# SAM9X60 device description
Architecture: ARM926EJS; Family: SAM9; Series: SAM9X
Registers are 32-bit, read-write, no defined reset value unless marked. A register's access mark holds for its fields unless they carry their own. Offsets are from the block's base; [hi:lo] are bit positions; {n}, {i} and the like mark numbered series; 'fields as' and 'values as' point back to an identical list; <NAME> marks a mode.

## FLEXCOM — Flexible Serial Communication
Instances: FLEXCOM{n} {0xF801C000+0x4000*n} (n=0..3), FLEXCOM4 0xF0000000, FLEXCOM5 0xF0004000, FLEXCOM6 0xF8010000, FLEXCOM7 0xF8014000, FLEXCOM8 0xF8018000, FLEXCOM9 0xF8040000, FLEXCOM10 0xF8044000, FLEXCOM11 0xF0020000, FLEXCOM12 0xF0024000
0x00 FLEX_MR — FLEXCOM Mode Register
  [1:0] OPMODE — FLEXCOM Operating Mode
    0=NO_COM (No communication); 1=USART (All UART related protocols are selected (RS232, RS485, IrDA, ISO7816, LIN, LON)SPI/TWI related registers are not accessible and have no impact on IOs.); 2=SPI (SPI operating mode is selected.USART/TWI related registers are not accessible and have no impact on IOs.); 3=TWI (All TWI related protocols are selected (TWI, SMBus).USART/SPI related registers are not accessible and have no impact on IOs.)
0x10 FLEX_RHR ro — FLEXCOM Receive Holding Register
  [15:0] RXDATA — Receive Data
0x20 FLEX_THR — FLEXCOM Transmit Holding Register
  [15:0] TXDATA — Transmit Data
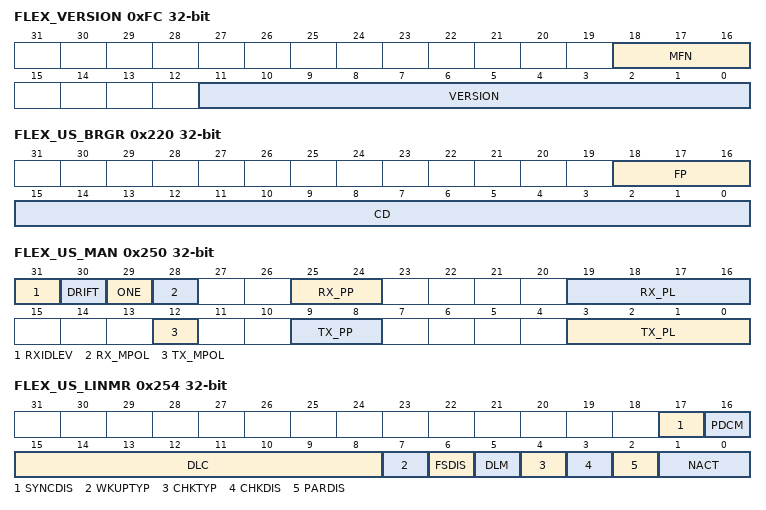
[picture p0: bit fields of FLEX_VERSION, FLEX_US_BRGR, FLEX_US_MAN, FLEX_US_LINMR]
0xFC FLEX_VERSION ro — FLEXCOM Version Register
  [18:16] MFN — Metal Fix Number
  [11:0] VERSION — Hardware Module Version
0x200 FLEX_US_CR wo — USART Control Register
  [31] FIFODIS <DEFAULT> — FIFO Disable
  [30] FIFOEN <DEFAULT> — FIFO Enable
  [28] REQCLR <DEFAULT> — Request to Clear the Comparison Trigger
  [26] TXFLCLR <DEFAULT> — Transmit FIFO Lock CLEAR
  [25] RXFCLR <DEFAULT> — Receive FIFO Clear
  [24] TXFCLR <DEFAULT> — Transmit FIFO Clear
  [21] LINWKUP <DEFAULT> — Send LIN Wakeup Signal
  [20] LINABT <DEFAULT> — Abort LIN Transmission
  [19] RTSDIS <DEFAULT> — Request to Send Disable
  [18] RTSEN <DEFAULT> — Request to Send Enable
  [17] DTRDIS <DEFAULT> — Data Terminal Ready Disable
  [16] DTREN <DEFAULT> — Data Terminal Ready Enable
  [15] RETTO <DEFAULT> — Start Timeout Immediately
  [14] RSTNACK <DEFAULT> — Reset Non Acknowledge
  [13] RSTIT <DEFAULT> — Reset Iterations
  [12] SENDA <DEFAULT> — Send Address
  [11] STTTO <DEFAULT> — Clear TIMEOUT Flag and Start Timeout After Next Character Received
  [10] STPBRK <DEFAULT> — Stop Break
  [9] STTBRK <DEFAULT> — Start Break
  [8] RSTSTA <DEFAULT> — Reset Status Bits
  [7] TXDIS <DEFAULT> — Transmitter Disable
  [6] TXEN <DEFAULT> — Transmitter Enable
  [5] RXDIS <DEFAULT> — Receiver Disable
  [4] RXEN <DEFAULT> — Receiver Enable
  [3] RSTTX <DEFAULT> — Reset Transmitter
  [2] RSTRX <DEFAULT> — Reset Receiver
  [19] RCS <SPI_MODE> — Release SPI Chip Select
  [18] FCS <SPI_MODE> — Force SPI Chip Select
  [8] RSTSTA <SPI_MODE> — Reset Status Bits
  [7] TXDIS <SPI_MODE> — Transmitter Disable
  [6] TXEN <SPI_MODE> — Transmitter Enable
  [5] RXDIS <SPI_MODE> — Receiver Disable
  [4] RXEN <SPI_MODE> — Receiver Enable
  [3] RSTTX <SPI_MODE> — Reset Transmitter
  [2] RSTRX <SPI_MODE> — Reset Receiver
0x204 FLEX_US_MR — USART Mode Register
  [31] ONEBIT <DEFAULT> — Start Frame Delimiter Selector
  [30] MODSYNC <DEFAULT> — Manchester Synchronization Mode
  [29] MAN <DEFAULT> — Manchester Encoder/Decoder Enable
  [28] FILTER <DEFAULT> — Receive Line Filter
  [26:24] MAX_ITERATION <DEFAULT> — Maximum Number of Automatic Iteration
  [23] INVDATA <DEFAULT> — Inverted Data
  [22] VAR_SYNC <DEFAULT> — Variable Synchronization of Command/Data Sync Start Frame Delimiter
  [21] DSNACK <DEFAULT> — Disable Successive NACK
  [20] INACK <DEFAULT> — Inhibit Non Acknowledge
  [19] OVER <DEFAULT> — Oversampling Mode
  [18] CLKO <DEFAULT> — Clock Output Select
  [17] MODE9 <DEFAULT> — 9-bit Character Length
  [16] MSBF <DEFAULT> — Bit Order
  [15:14] CHMODE <DEFAULT> — Channel Mode
    0=NORMAL (Normal mode); 1=AUTOMATIC (Automatic Echo. Receiver input is connected to the TXD pin.); 2=LOCAL_LOOPBACK (Local Loopback. Transmitter output is connected to the Receiver Input.); 3=REMOTE_LOOPBACK (Remote Loopback. RXD pin is internally connected to the TXD pin.)
  [13:12] NBSTOP <DEFAULT> — Number of Stop Bits
    0=_1_BIT (1 stop bit); 1=_1_5_BIT (1.5 stop bit (SYNC = 0) or reserved (SYNC = 1)); 2=_2_BIT (2 stop bits)
  [11:9] PAR <DEFAULT> — Parity Type
    0=EVEN (Even parity); 1=ODD (Odd parity); 2=SPACE (Parity forced to 0 (Space)); 3=MARK (Parity forced to 1 (Mark)); 4=NO (No parity); 6=MULTIDROP (Multidrop mode)
  [8] SYNC <DEFAULT> — Synchronous Mode Select
  [7:6] CHRL <DEFAULT> — Character Length
    {v}=_{v+5}_BIT (Character length is {v+5} bits) (v=0..3)
  [5:4] USCLKS <DEFAULT> — Clock Selection
    0=MCK (Peripheral clock is selected); 1=DIV (Peripheral clock divided (DIV = 8) is selected); 2=GCLK (PMC generic clock is selected. If the SCK pin is driven (CLKO = 1), the CD field must be greater than 1.); 3=SCK (External pin SCK is selected)
  [3:0] USART_MODE <DEFAULT> — USART Mode of Operation
    0=NORMAL (Normal mode); 1=RS485; 2=HW_HANDSHAKING (Hardware handshaking); 3=MODEM; 4=IS07816_T_0 (IS07816 Protocol: T = 0); 6=IS07816_T_1 (IS07816 Protocol: T = 1); 8=IRDA; 9=LON; 10=LIN_MASTER (LIN Master mode); 11=LIN_SLAVE (LIN Slave mode); 12=DATA16BIT_MASTER (16-bit data master); 13=DATA16BIT_SLAVE (16-bit data slave); 14=SPI_MASTER (SPI Master mode (CLKO must be written to 1 and USCLKS = 0, 1 or 2)); 15=SPI_SLAVE (SPI Slave mode)
  [20] WRDBT <SPI_MODE> — Wait Read Data Before Transfer
  [16] CPOL <SPI_MODE> — SPI Clock Polarity
  [15:14] CHMODE <SPI_MODE> — Channel Mode
    0=NORMAL (Normal mode)
  [8] CPHA <SPI_MODE> — SPI Clock Phase
  [7:6] CHRL <SPI_MODE> — Character Length
    3=_8_BIT (Character length is 8 bits)
  [5:4] USCLKS <SPI_MODE> — Clock Selection
    0=MCK (Peripheral clock is selected); 1=DIV (Peripheral clock Divided (DIV= 8) is selected); 2=GCLK (A PMC generic clock is selected); 3=SCK (External pin SCK is selected)
  [3:0] USART_MODE <SPI_MODE> — USART Mode of Operation
    14=SPI_MASTER; 15=SPI_SLAVE
0x208 FLEX_US_IER wo — USART Interrupt Enable Register
  [24] MANE <DEFAULT> — Manchester Error Interrupt Enable
  [22] CMP <DEFAULT> — Comparison Interrupt Enable
  [19] CTSIC <DEFAULT> — Clear to Send Input Change Interrupt Enable
  [18] DCDIC <DEFAULT> — Data Carrier Detect Input Change Interrupt Enable
  [17] DSRIC <DEFAULT> — Data Set Ready Input Change Enable
  [16] RIIC <DEFAULT> — Ring Indicator Input Change Enable
  [13] NACK <DEFAULT> — Non Acknowledge Interrupt Enable
  [10] ITER <DEFAULT> — Max number of Repetitions Reached Interrupt Enable
  [9] TXEMPTY <DEFAULT> — TXEMPTY Interrupt Enable
  [8] TIMEOUT <DEFAULT> — Timeout Interrupt Enable
  [7] PARE <DEFAULT> — Parity Error Interrupt Enable
  [6] FRAME <DEFAULT> — Framing Error Interrupt Enable
  [5] OVRE <DEFAULT> — Overrun Error Interrupt Enable
  [2] RXBRK <DEFAULT> — Receiver Break Interrupt Enable
  [1] TXRDY <DEFAULT> — TXRDY Interrupt Enable
  [0] RXRDY <DEFAULT> — RXRDY Interrupt Enable
  [31] LINHTE <LIN_MODE> — LIN Header Timeout Error Interrupt Enable
  [30] LINSTE <LIN_MODE> — LIN Synch Tolerance Error Interrupt Enable
  [29] LINSNRE <LIN_MODE> — LIN Slave Not Responding Error Interrupt Enable
  [28] LINCE <LIN_MODE> — LIN Checksum Error Interrupt Enable
  [27] LINIPE <LIN_MODE> — LIN Identifier Parity Interrupt Enable
  [26] LINISFE <LIN_MODE> — LIN Inconsistent Synch Field Error Interrupt Enable
  [25] LINBE <LIN_MODE> — LIN Bus Error Interrupt Enable
  [15] LINTC <LIN_MODE> — LIN Transfer Completed Interrupt Enable
  [14] LINID <LIN_MODE> — LIN Identifier Sent or LIN Identifier Received Interrupt Enable
  [13] LINBK <LIN_MODE> — LIN Break Sent or LIN Break Received Interrupt Enable
  [9] TXEMPTY <LIN_MODE> — TXEMPTY Interrupt Enable
  [8] TIMEOUT <LIN_MODE> — Timeout Interrupt Enable
  [7] PARE <LIN_MODE> — Parity Error Interrupt Enable
  [6] FRAME <LIN_MODE> — Framing Error Interrupt Enable
  [5] OVRE <LIN_MODE> — Overrun Error Interrupt Enable
  [1] TXRDY <LIN_MODE> — TXRDY Interrupt Enable
  [0] RXRDY <LIN_MODE> — RXRDY Interrupt Enable
  [28] LBLOVFE <LON_MODE> — LON Backlog Overflow Error Interrupt Enable
  [27] LRXD <LON_MODE> — LON Reception Done Interrupt Enable
  [26] LFET <LON_MODE> — LON Frame Early Termination Interrupt Enable
  [25] LCOL <LON_MODE> — LON Collision Interrupt Enable
  [24] LTXD <LON_MODE> — LON Transmission Done Interrupt Enable
  [10] UNRE <LON_MODE> — Underrun Error Interrupt Enable
  [9] TXEMPTY <LON_MODE> — TXEMPTY Interrupt Enable
  [7] LCRCE <LON_MODE> — LON CRC Error Interrupt Enable
  [6] LSFE <LON_MODE> — LON Short Frame Error Interrupt Enable
  [5] OVRE <LON_MODE> — Overrun Error Interrupt Enable
  [1] TXRDY <LON_MODE> — TXRDY Interrupt Enable
  [0] RXRDY <LON_MODE> — RXRDY Interrupt Enable
  [22] CMP <SPI_MODE> — Comparison Interrupt Enable
  [19] NSSE <SPI_MODE> — NSS Line (Driving CTS Pin) Rising or Falling Edge Event
  [10] UNRE <SPI_MODE> — SPI Underrun Error Interrupt Enable
  [9] TXEMPTY <SPI_MODE> — TXEMPTY Interrupt Enable
  [5] OVRE <SPI_MODE> — Overrun Error Interrupt Enable
  [1] TXRDY <SPI_MODE> — TXRDY Interrupt Enable
  [0] RXRDY <SPI_MODE> — RXRDY Interrupt Enable
0x20C FLEX_US_IDR wo — USART Interrupt Disable Register
  [24] MANE <DEFAULT> — Manchester Error Interrupt Disable
  [22] CMP <DEFAULT> — Comparison Interrupt Disable
  [19] CTSIC <DEFAULT> — Clear to Send Input Change Interrupt Disable
  [18] DCDIC <DEFAULT> — Data Carrier Detect Input Change Interrupt Disable
  [17] DSRIC <DEFAULT> — Data Set Ready Input Change Disable
  [16] RIIC <DEFAULT> — Ring Indicator Input Change Disable
  [13] NACK <DEFAULT> — Non Acknowledge Interrupt Disable
  [10] ITER <DEFAULT> — Max Number of Repetitions Reached Interrupt Disable
  [9] TXEMPTY <DEFAULT> — TXEMPTY Interrupt Disable
  [8] TIMEOUT <DEFAULT> — Timeout Interrupt Disable
  [7] PARE <DEFAULT> — Parity Error Interrupt Disable
  [6] FRAME <DEFAULT> — Framing Error Interrupt Disable
  [5] OVRE <DEFAULT> — Overrun Error Interrupt Enable
  [2] RXBRK <DEFAULT> — Receiver Break Interrupt Disable
  [1] TXRDY <DEFAULT> — TXRDY Interrupt Disable
  [0] RXRDY <DEFAULT> — RXRDY Interrupt Disable
  [31] LINHTE <LIN_MODE> — LIN Header Timeout Error Interrupt Disable
  [30] LINSTE <LIN_MODE> — LIN Synch Tolerance Error Interrupt Disable
  [29] LINSNRE <LIN_MODE> — LIN Slave Not Responding Error Interrupt Disable
  [28] LINCE <LIN_MODE> — LIN Checksum Error Interrupt Disable
  [27] LINIPE <LIN_MODE> — LIN Identifier Parity Interrupt Disable
  [26] LINISFE <LIN_MODE> — LIN Inconsistent Synch Field Error Interrupt Disable
  [25] LINBE <LIN_MODE> — LIN Bus Error Interrupt Disable
  [15] LINTC <LIN_MODE> — LIN Transfer Completed Interrupt Disable
  [14] LINID <LIN_MODE> — LIN Identifier Sent or LIN Identifier Received Interrupt Disable
  [13] LINBK <LIN_MODE> — LIN Break Sent or LIN Break Received Interrupt Disable
  [9] TXEMPTY <LIN_MODE> — TXEMPTY Interrupt Disable
  [8] TIMEOUT <LIN_MODE> — Timeout Interrupt Disable
  [7] PARE <LIN_MODE> — Parity Error Interrupt Disable
  [6] FRAME <LIN_MODE> — Framing Error Interrupt Disable
  [5] OVRE <LIN_MODE> — Overrun Error Interrupt Disable
  [1] TXRDY <LIN_MODE> — TXRDY Interrupt Disable
  [0] RXRDY <LIN_MODE> — RXRDY Interrupt Disable
  [28] LBLOVFE <LON_MODE> — LON Backlog Overflow Error Interrupt Disable
  [27] LRXD <LON_MODE> — LON Reception Done Interrupt Disable
  [26] LFET <LON_MODE> — LON Frame Early Termination Interrupt Disable
  [25] LCOL <LON_MODE> — LON Collision Interrupt Disable
  [24] LTXD <LON_MODE> — LON Transmission Done Interrupt Disable
  [10] UNRE <LON_MODE> — Underrun Error Interrupt Disable
  [9] TXEMPTY <LON_MODE> — TXEMPTY Interrupt Disable
  [7] LCRCE <LON_MODE> — LON CRC Error Interrupt Disable
  [6] LSFE <LON_MODE> — LON Short Frame Error Interrupt Disable
  [5] OVRE <LON_MODE> — Overrun Error Interrupt Disable
  [1] TXRDY <LON_MODE> — TXRDY Interrupt Disable
  [0] RXRDY <LON_MODE> — RXRDY Interrupt Disable
  [22] CMP <SPI_MODE> — Comparison Interrupt Disable
  [19] NSSE <SPI_MODE> — NSS Line (Driving CTS Pin) Rising or Falling Edge Event
  [10] UNRE <SPI_MODE> — SPI Underrun Error Interrupt Disable
  [9] TXEMPTY <SPI_MODE> — TXEMPTY Interrupt Disable
  [5] OVRE <SPI_MODE> — Overrun Error Interrupt Disable
  [1] TXRDY <SPI_MODE> — TXRDY Interrupt Disable
  [0] RXRDY <SPI_MODE> — RXRDY Interrupt Disable
0x210 FLEX_US_IMR ro — USART Interrupt Mask Register
  [24] MANE <DEFAULT> — Manchester Error Interrupt Mask
  [22] CMP <DEFAULT> — Comparison Interrupt Mask
  [19] CTSIC <DEFAULT> — Clear to Send Input Change Interrupt Mask
  [18] DCDIC <DEFAULT> — Data Carrier Detect Input Change Interrupt Mask
  [17] DSRIC <DEFAULT> — Data Set Ready Input Change Mask
  [16] RIIC <DEFAULT> — Ring Indicator Input Change Mask
  [13] NACK <DEFAULT> — Non Acknowledge Interrupt Mask
  [10] ITER <DEFAULT> — Max Number of Repetitions Reached Interrupt Mask
  [9] TXEMPTY <DEFAULT> — TXEMPTY Interrupt Mask
  [8] TIMEOUT <DEFAULT> — Timeout Interrupt Mask
  [7] PARE <DEFAULT> — Parity Error Interrupt Mask
  [6] FRAME <DEFAULT> — Framing Error Interrupt Mask
  [5] OVRE <DEFAULT> — Overrun Error Interrupt Mask
  [2] RXBRK <DEFAULT> — Receiver Break Interrupt Mask
  [1] TXRDY <DEFAULT> — TXRDY Interrupt Mask
  [0] RXRDY <DEFAULT> — RXRDY Interrupt Mask
  [31] LINHTE <LIN_MODE> — LIN Header Timeout Error Interrupt Mask
  [30] LINSTE <LIN_MODE> — LIN Synch Tolerance Error Interrupt Mask
  [29] LINSNRE <LIN_MODE> — LIN Slave Not Responding Error Interrupt Mask
  [28] LINCE <LIN_MODE> — LIN Checksum Error Interrupt Mask
  [27] LINIPE <LIN_MODE> — LIN Identifier Parity Interrupt Mask
  [26] LINISFE <LIN_MODE> — LIN Inconsistent Synch Field Error Interrupt Mask
  [25] LINBE <LIN_MODE> — LIN Bus Error Interrupt Mask
  [15] LINTC <LIN_MODE> — LIN Transfer Completed Interrupt Mask
  [14] LINID <LIN_MODE> — LIN Identifier Sent or LIN Identifier Received Interrupt Mask
  [13] LINBK <LIN_MODE> — LIN Break Sent or LIN Break Received Interrupt Mask
  [9] TXEMPTY <LIN_MODE> — TXEMPTY Interrupt Mask
  [8] TIMEOUT <LIN_MODE> — Timeout Interrupt Mask
  [7] PARE <LIN_MODE> — Parity Error Interrupt Mask
  [6] FRAME <LIN_MODE> — Framing Error Interrupt Mask
  [5] OVRE <LIN_MODE> — Overrun Error Interrupt Mask
  [1] TXRDY <LIN_MODE> — TXRDY Interrupt Mask
  [0] RXRDY <LIN_MODE> — RXRDY Interrupt Mask
  [28] LBLOVFE <LON_MODE> — LON Backlog Overflow Error Interrupt Mask
  [27] LRXD <LON_MODE> — LON Reception Done Interrupt Mask
  [26] LFET <LON_MODE> — LON Frame Early Termination Interrupt Mask
  [25] LCOL <LON_MODE> — LON Collision Interrupt Mask
  [24] LTXD <LON_MODE> — LON Transmission Done Interrupt Mask
  [10] UNRE <LON_MODE> — Underrun Error Interrupt Mask
  [9] TXEMPTY <LON_MODE> — TXEMPTY Interrupt Mask
  [7] LCRCE <LON_MODE> — LON CRC Error Interrupt Mask
  [6] LSFE <LON_MODE> — LON Short Frame Error Interrupt Mask
  [5] OVRE <LON_MODE> — Overrun Error Interrupt Mask
  [1] TXRDY <LON_MODE> — TXRDY Interrupt Mask
  [0] RXRDY <LON_MODE> — RXRDY Interrupt Mask
  [22] CMP <SPI_MODE> — Comparison Interrupt Mask
  [19] NSSE <SPI_MODE> — NSS Line (Driving CTS Pin) Rising or Falling Edge Event
  [10] UNRE <SPI_MODE> — SPI Underrun Error Interrupt Mask
  [9] TXEMPTY <SPI_MODE> — TXEMPTY Interrupt Mask
  [5] OVRE <SPI_MODE> — Overrun Error Interrupt Mask
  [1] TXRDY <SPI_MODE> — TXRDY Interrupt Mask
  [0] RXRDY <SPI_MODE> — RXRDY Interrupt Mask
0x214 FLEX_US_CSR ro — USART Channel Status Register
  [24] MANE <DEFAULT> — Manchester Error
  [23] CTS <DEFAULT> — Image of CTS Input
  [22] CMP <DEFAULT> — Comparison Status
  [19] CTSIC <DEFAULT> — Clear to Send Input Change Flag
  [18] DCDIC <DEFAULT> — Data Carrier Detect Input Change Flag
  [17] DSRIC <DEFAULT> — Data Set Ready Input Change Flag
  [16] RIIC <DEFAULT> — Ring Indicator Input Change Flag
  [13] NACK <DEFAULT> — Non Acknowledge Interrupt
  [10] ITER <DEFAULT> — Max Number of Repetitions Reached
  [9] TXEMPTY <DEFAULT> — Transmitter Empty (cleared by writing FLEX_US_THR)
  [8] TIMEOUT <DEFAULT> — Receiver Timeout
  [7] PARE <DEFAULT> — Parity Error
  [6] FRAME <DEFAULT> — Framing Error
  [5] OVRE <DEFAULT> — Overrun Error
  [2] RXBRK <DEFAULT> — Break Received/End of Break
  [1] TXRDY <DEFAULT> — Transmitter Ready (cleared by writing FLEX_US_THR)
  [0] RXRDY <DEFAULT> — Receiver Ready (cleared by reading FLEX_US_RHR)
  [31] LINHTE <LIN_MODE> — LIN Header Timeout Error
  [30] LINSTE <LIN_MODE> — LIN Synch Tolerance Error
  [29] LINSNRE <LIN_MODE> — LIN Slave Not Responding Error
  [28] LINCE <LIN_MODE> — LIN Checksum Error
  [27] LINIPE <LIN_MODE> — LIN Identifier Parity Error
  [26] LINISFE <LIN_MODE> — LIN Inconsistent Synch Field Error
  [25] LINBE <LIN_MODE> — LIN Bit Error
  [23] LINBLS <LIN_MODE> — LIN Bus Line Status
  [15] LINTC <LIN_MODE> — LIN Transfer Completed
  [14] LINID <LIN_MODE> — LIN Identifier Sent or LIN Identifier Received
  [13] LINBK <LIN_MODE> — LIN Break Sent or LIN Break Received
  [9] TXEMPTY <LIN_MODE> — Transmitter Empty (cleared by writing FLEX_US_THR)
  [8] TIMEOUT <LIN_MODE> — Receiver Timeout
  [7] PARE <LIN_MODE> — Parity Error
  [6] FRAME <LIN_MODE> — Framing Error
  [5] OVRE <LIN_MODE> — Overrun Error
  [1] TXRDY <LIN_MODE> — Transmitter Ready (cleared by writing FLEX_US_THR)
  [0] RXRDY <LIN_MODE> — Receiver Ready (cleared by reading FLEX_US_RHR)
  [28] LBLOVFE <LON_MODE> — LON Backlog Overflow Error
  [27] LRXD <LON_MODE> — LON Reception End Flag
  [26] LFET <LON_MODE> — LON Frame Early Termination
  [25] LCOL <LON_MODE> — LON Collision Detected Flag
  [24] LTXD <LON_MODE> — LON Transmission End Flag
  [10] UNRE <LON_MODE> — Underrun Error
  [9] TXEMPTY <LON_MODE> — Transmitter Empty (cleared by writing FLEX_US_THR)
  [7] LCRCE <LON_MODE> — LON CRC Error
  [6] LSFE <LON_MODE> — LON Short Frame Error
  [5] OVRE <LON_MODE> — Overrun Error
  [1] TXRDY <LON_MODE> — Transmitter Ready (cleared by writing FLEX_US_THR)
  [0] RXRDY <LON_MODE> — Receiver Ready (cleared by reading FLEX_US_RHR)
  [23] NSS <SPI_MODE> — NSS Line (Driving CTS Pin) Rising or Falling Edge Event (cleared on read)
  [22] CMP <SPI_MODE> — Comparison Match
  [19] NSSE <SPI_MODE> — NSS Line (Driving CTS Pin) Rising or Falling Edge Event (cleared on read)
  [10] UNRE <SPI_MODE> — Underrun Error
  [9] TXEMPTY <SPI_MODE> — Transmitter Empty (cleared by writing FLEX_US_THR)
  [5] OVRE <SPI_MODE> — Overrun Error
  [1] TXRDY <SPI_MODE> — Transmitter Ready (cleared by writing FLEX_US_THR)
  [0] RXRDY <SPI_MODE> — Receiver Ready (cleared by reading FLEX_US_RHR)
0x218 FLEX_US_RHR ro — USART Receive Holding Register
  [15] RXSYNH <DEFAULT> — Received Sync
  [8:0] RXCHR <DEFAULT> — Received Character
  [8n+7:8n] RXCHR{n} <FIFO_MULTI_DATA> (n=0..3) — Received Character
0x21C FLEX_US_THR wo — USART Transmit Holding Register
  [15] TXSYNH <DEFAULT> — Sync Field to be Transmitted
  [8:0] TXCHR <DEFAULT> — Character to be Transmitted
  [8n+7:8n] TXCHR{n} <FIFO_MULTI_DATA> (n=0..3) — Character to be Transmitted
0x220 FLEX_US_BRGR — USART Baud Rate Generator Register
  [18:16] FP — Fractional Part
  [15:0] CD — Clock Divider
0x224 FLEX_US_RTOR — USART Receiver Timeout Register
  [16:0] TO — Timeout Value
0x228 FLEX_US_TTGR — USART Transmitter Timeguard Register
  [7:0] TG <DEFAULT> — Timeguard Value
  [23:0] PCYCLE <LON_MODE> — LON PCYCLE Length
0x240 FLEX_US_FIDI — USART FI DI Ratio Register
  [15:0] FI_DI_RATIO <DEFAULT> — FI Over DI Ratio Value
  [23:0] BETA2 <LON_MODE> — LON BETA2 Length
0x244 FLEX_US_NER ro — USART Number of Errors Register
  [7:0] NB_ERRORS — Number of Errors
0x24C FLEX_US_IF — USART IrDA Filter Register
  [7:0] IRDA_FILTER
0x250 FLEX_US_MAN — USART Manchester Configuration Register
  [31] RXIDLEV — Receiver Idle Value
  [30] DRIFT — Drift Compensation
  [29] ONE — Must Be Set to 1
  [28] RX_MPOL — Receiver Manchester Polarity
  [25:24] RX_PP — Receiver Preamble Pattern detected
    0=ALL_ONE (The preamble is composed of '1's); 1=ALL_ZERO (The preamble is composed of '0's); 2=ZERO_ONE (The preamble is composed of '01's); 3=ONE_ZERO (The preamble is composed of '10's)
  [19:16] RX_PL — Receiver Preamble Length
  [12] TX_MPOL — Transmitter Manchester Polarity
  [9:8] TX_PP — Transmitter Preamble Pattern
    values as RX_PP
  [3:0] TX_PL — Transmitter Preamble Length
0x254 FLEX_US_LINMR — USART LIN Mode Register
  [17] SYNCDIS — Synchronization Disable
  [16] PDCM — DMA Mode
  [15:8] DLC — Data Length Control
  [7] WKUPTYP — Wakeup Signal Type
  [6] FSDIS — Frame Slot Mode Disable
  [5] DLM — Data Length Mode
  [4] CHKTYP — Checksum Type
  [3] CHKDIS — Checksum Disable
  [2] PARDIS — Parity Disable
  [1:0] NACT — LIN Node Action
    0=PUBLISH (The USART transmits the response.); 1=SUBSCRIBE (The USART receives the response.); 2=IGNORE (The USART does not transmit and does not receive the response.)
0x258 FLEX_US_LINIR — USART LIN Identifier Register
  [7:0] IDCHR — Identifier Character
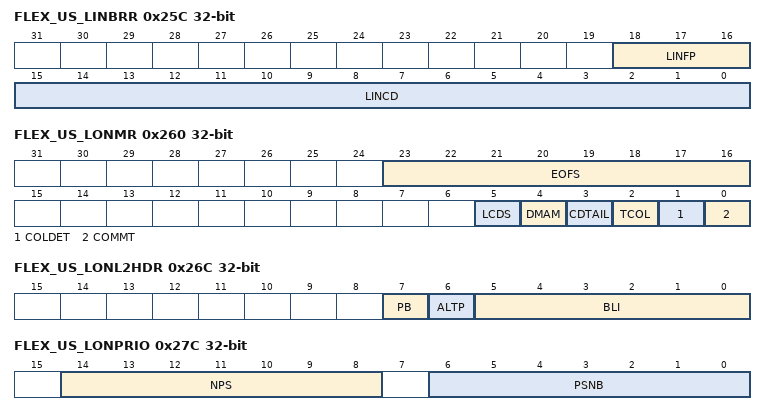
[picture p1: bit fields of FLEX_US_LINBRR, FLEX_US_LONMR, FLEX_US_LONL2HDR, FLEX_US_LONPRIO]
0x25C FLEX_US_LINBRR ro — USART LIN Baud Rate Register
  [18:16] LINFP — Fractional Part after Synchronization
  [15:0] LINCD — Clock Divider after Synchronization
0x260 FLEX_US_LONMR — USART LON Mode Register
  [23:16] EOFS — End of Frame Condition Size
  [5] LCDS — LON Collision Detection Source
  [4] DMAM — LON DMA Mode
  [3] CDTAIL — LON Collision Detection on Frame Tail
  [2] TCOL — Terminate Frame upon Collision Notification
  [1] COLDET — LON Collision Detection Feature
  [0] COMMT — LON comm_type Parameter Value
0x264 FLEX_US_LONPR — USART LON Preamble Register
  [13:0] LONPL — LON Preamble Length
0x268 FLEX_US_LONDL — USART LON Data Length Register
  [7:0] LONDL — LON Data Length
0x26C FLEX_US_LONL2HDR — USART LON L2HDR Register
  [7] PB — LON Priority Bit
  [6] ALTP — LON Alternate Path Bit
  [5:0] BLI — LON Backlog Increment
0x270 FLEX_US_LONBL ro — USART LON Backlog Register
  [5:0] LONBL — LON Node Backlog Value
0x274 FLEX_US_LONB1TX — USART LON Beta1 Tx Register
  [23:0] BETA1TX — LON Beta1 Length after Transmission
0x278 FLEX_US_LONB1RX — USART LON Beta1 Rx Register
  [23:0] BETA1RX — LON Beta1 Length after Reception
0x27C FLEX_US_LONPRIO — USART LON Priority Register
  [14:8] NPS — LON Node Priority Slot
  [6:0] PSNB — LON Priority Slot Number
0x280 FLEX_US_IDTTX — USART LON IDT Tx Register
  [23:0] IDTTX — LON Indeterminate Time after Transmission (comm_type = 1 mode only)
0x284 FLEX_US_IDTRX — USART LON IDT Rx Register
  [23:0] IDTRX — LON Indeterminate Time after Reception (comm_type = 1 mode only)
0x288 FLEX_US_ICDIFF — USART IC DIFF Register
  [3:0] ICDIFF — IC Differentiator Number
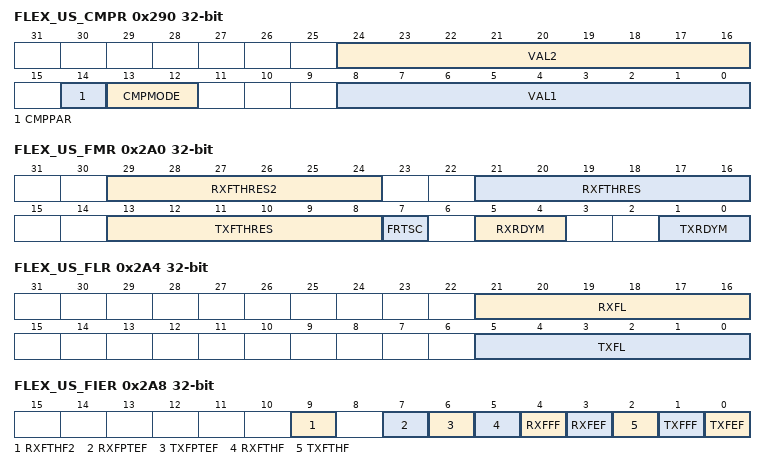
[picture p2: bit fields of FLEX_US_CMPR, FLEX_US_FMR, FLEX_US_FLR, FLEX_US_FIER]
0x290 FLEX_US_CMPR — USART Comparison Register
  [24:16] VAL2 — Second Comparison Value for Received Character
  [14] CMPPAR — Compare Parity
  [13:12] CMPMODE — Comparison Mode
    0=FLAG_ONLY (Any character is received and comparison function drives CMP flag.); 1=START_CONDITION (Comparison condition must be met to start reception.); 2=FILTER (Comparison must be met to receive the current data only)
  [8:0] VAL1 — First Comparison Value for Received Character
0x2A0 FLEX_US_FMR — USART FIFO Mode Register
  [29:24] RXFTHRES2 — Receive FIFO Threshold 2
  [21:16] RXFTHRES — Receive FIFO Threshold
  [13:8] TXFTHRES — Transmit FIFO Threshold
  [7] FRTSC — FIFO RTS Pin Control enable (Hardware Handshaking mode only)
  [5:4] RXRDYM — Receiver Ready Mode
    0=ONE_DATA (RXRDY will be at level '1' when at least one unread data is in the Receive FIFO); 1=TWO_DATA (RXRDY will be at level '1' when at least two unread data are in the Receive FIFO); 2=FOUR_DATA (RXRDY will be at level '1' when at least four unread data are in the Receive FIFO)
  [1:0] TXRDYM — Transmitter Ready Mode
    0=ONE_DATA (TXRDY will be at level '1' when at least one data can be written in the Transmit FIFO); 1=TWO_DATA (TXRDY will be at level '1' when at least two data can be written in the Transmit FIFO); 2=FOUR_DATA (TXRDY will be at level '1' when at least four data can be written in the Transmit FIFO)
0x2A4 FLEX_US_FLR ro — USART FIFO Level Register
  [21:16] RXFL — Receive FIFO Level
  [5:0] TXFL — Transmit FIFO Level
0x2A8 FLEX_US_FIER wo — USART FIFO Interrupt Enable Register
  [9] RXFTHF2 — RXFTHF2 Interrupt Enable
  [7] RXFPTEF — RXFPTEF Interrupt Enable
  [6] TXFPTEF — TXFPTEF Interrupt Enable
  [5] RXFTHF — RXFTHF Interrupt Enable
  [4] RXFFF — RXFFF Interrupt Enable
  [3] RXFEF — RXFEF Interrupt Enable
  [2] TXFTHF — TXFTHF Interrupt Enable
  [1] TXFFF — TXFFF Interrupt Enable
  [0] TXFEF — TXFEF Interrupt Enable
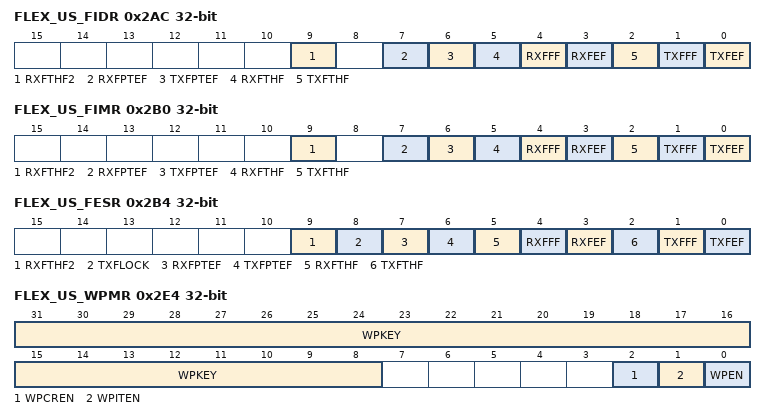
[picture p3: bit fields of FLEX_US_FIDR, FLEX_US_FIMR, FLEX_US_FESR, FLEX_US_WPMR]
0x2AC FLEX_US_FIDR wo — USART FIFO Interrupt Disable Register
  [9] RXFTHF2 — RXFTHF2 Interrupt Disable
  [7] RXFPTEF — RXFPTEF Interrupt Disable
  [6] TXFPTEF — TXFPTEF Interrupt Disable
  [5] RXFTHF — RXFTHF Interrupt Disable
  [4] RXFFF — RXFFF Interrupt Disable
  [3] RXFEF — RXFEF Interrupt Disable
  [2] TXFTHF — TXFTHF Interrupt Disable
  [1] TXFFF — TXFFF Interrupt Disable
  [0] TXFEF — TXFEF Interrupt Disable
0x2B0 FLEX_US_FIMR ro — USART FIFO Interrupt Mask Register
  [9] RXFTHF2 — RXFTHF2 Interrupt Mask
  [7] RXFPTEF — RXFPTEF Interrupt Mask
  [6] TXFPTEF — TXFPTEF Interrupt Mask
  [5] RXFTHF — RXFTHF Interrupt Mask
  [4] RXFFF — RXFFF Interrupt Mask
  [3] RXFEF — RXFEF Interrupt Mask
  [2] TXFTHF — TXFTHF Interrupt Mask
  [1] TXFFF — TXFFF Interrupt Mask
  [0] TXFEF — TXFEF Interrupt Mask
0x2B4 FLEX_US_FESR ro — USART FIFO Event Status Register
  [9] RXFTHF2 — Receive FIFO Threshold Flag 2 (cleared by writing the FLEX_US_CR.RSTSTA bit)
  [8] TXFLOCK — Transmit FIFO Lock
  [7] RXFPTEF — Receive FIFO Pointer Error Flag
  [6] TXFPTEF — Transmit FIFO Pointer Error Flag
  [5] RXFTHF — Receive FIFO Threshold Flag (cleared by writing the FLEX_US_CR.RSTSTA bit)
  [4] RXFFF — Receive FIFO Full Flag (cleared by writing the FLEX_US_CR.RSTSTA bit)
  [3] RXFEF — Receive FIFO Empty Flag (cleared by writing the FLEX_US_CR.RSTSTA bit)
  [2] TXFTHF — Transmit FIFO Threshold Flag (cleared by writing the FLEX_US_CR.RSTSTA bit)
  [1] TXFFF — Transmit FIFO Full Flag (cleared by writing the FLEX_US_CR.RSTSTA bit)
  [0] TXFEF — Transmit FIFO Empty Flag (cleared by writing the FLEX_US_CR.RSTSTA bit)
0x2E4 FLEX_US_WPMR — USART Write Protection Mode Register
  [31:8] WPKEY — Write Protection Key
    0x555341=PASSWD (Writing any other value in this field aborts the write operation of bits WPEN, WPITEN and WPCREN. Always reads as 0.)
  [2] WPCREN — Write Protection Control Enable
  [1] WPITEN — Write Protection Interrupt Enable
  [0] WPEN — Write Protection Enable
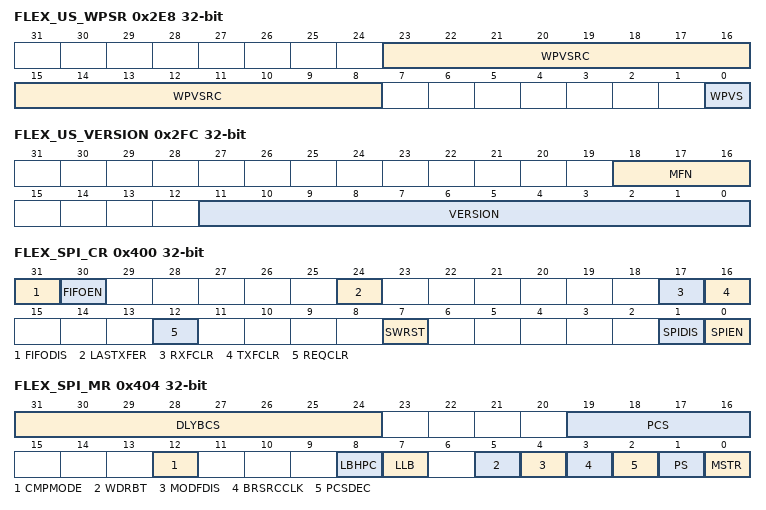
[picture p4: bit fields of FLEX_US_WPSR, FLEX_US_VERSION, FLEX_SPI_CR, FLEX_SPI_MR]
0x2E8 FLEX_US_WPSR ro — USART Write Protection Status Register
  [23:8] WPVSRC — Write Protection Violation Source
  [0] WPVS — Write Protection Violation Status
0x2FC FLEX_US_VERSION ro — USART Version Register
  fields as FLEX_VERSION
0x400 FLEX_SPI_CR wo — SPI Control Register
  [31] FIFODIS — FIFO Disable
  [30] FIFOEN — FIFO Enable
  [24] LASTXFER — Last Transfer
  [17] RXFCLR — Receive FIFO Clear
  [16] TXFCLR — Transmit FIFO Clear
  [12] REQCLR — Request to Clear the Comparison Trigger
  [7] SWRST — SPI Software Reset
  [1] SPIDIS — SPI Disable
  [0] SPIEN — SPI Enable
0x404 FLEX_SPI_MR — SPI Mode Register
  [31:24] DLYBCS — Delay Between Chip Selects
  [19:16] PCS — Peripheral Chip Select
  [12] CMPMODE — Comparison Mode
    0=FLAG_ONLY (Any character is received and comparison function drives CMP flag.); 1=START_CONDITION (Comparison condition must be met to start reception of all incoming characters until REQCLR is set.)
  [8] LBHPC — Last Bit Half Period Compatibility
  [7] LLB — Local Loopback Enable
  [5] WDRBT — Wait Data Read Before Transfer
  [4] MODFDIS — Mode Fault Detection
  [3] BRSRCCLK — Bit Rate Source Clock
    0=PERIPH_CLK (The peripheral clock is the source clock for the bit rate generation.); 1=GCLK (GCLK is the source clock for the bit rate generation, thus the bit rate can be independent of the core/peripheral clock.)
  [2] PCSDEC — Chip Select Decode
  [1] PS — Peripheral Select
  [0] MSTR — Master/Slave Mode
0x408 FLEX_SPI_RDR ro — SPI Receive Data Register
  [19:16] PCS <DEFAULT> — Peripheral Chip Select
  [15:0] RD <DEFAULT> — Receive Data
  [31:16] RD1 <FIFO_MULTI_DATA_16> — Receive Data
  [15:0] RD0 <FIFO_MULTI_DATA_16> — Receive Data
  [31:24] RD3 <FIFO_MULTI_DATA_8> — Receive Data
  [23:16] RD2 <FIFO_MULTI_DATA_8> — Receive Data
  [15:8] RD1 <FIFO_MULTI_DATA_8> — Receive Data
  [7:0] RD0 <FIFO_MULTI_DATA_8> — Receive Data
0x40C FLEX_SPI_TDR wo — SPI Transmit Data Register
  [24] LASTXFER <DEFAULT> — Last Transfer
  [19:16] PCS <DEFAULT> — Peripheral Chip Select
  [15:0] TD <DEFAULT> — Transmit Data
  [31:16] TD1 <FIFO_MULTI_DATA> — Transmit Data
  [15:0] TD0 <FIFO_MULTI_DATA> — Transmit Data
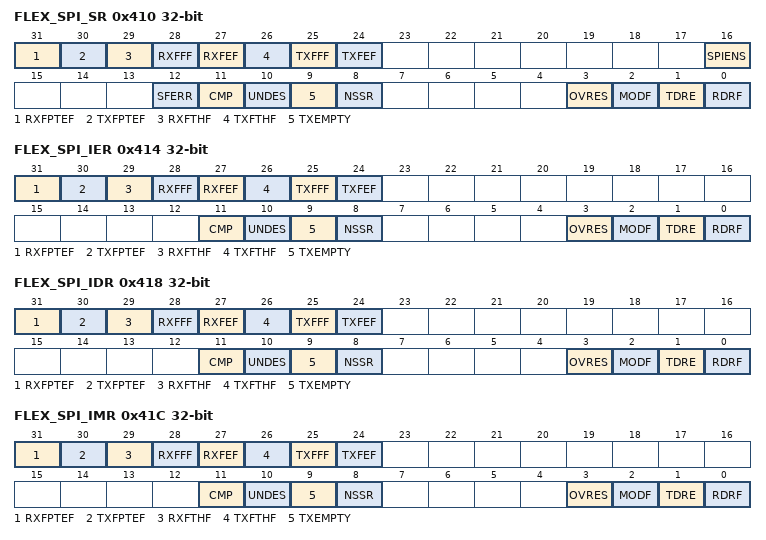
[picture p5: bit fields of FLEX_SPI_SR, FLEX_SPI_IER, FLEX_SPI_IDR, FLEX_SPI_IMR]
0x410 FLEX_SPI_SR ro — SPI Status Register
  [31] RXFPTEF — Receive FIFO Pointer Error Flag
  [30] TXFPTEF — Transmit FIFO Pointer Error Flag
  [29] RXFTHF — Receive FIFO Threshold Flag
  [28] RXFFF — Receive FIFO Full Flag
  [27] RXFEF — Receive FIFO Empty Flag
  [26] TXFTHF — Transmit FIFO Threshold Flag (cleared on read)
  [25] TXFFF — Transmit FIFO Full Flag (cleared on read)
  [24] TXFEF — Transmit FIFO Empty Flag (cleared on read)
  [16] SPIENS — SPI Enable Status
  [12] SFERR — Slave Frame Error (cleared on read)
  [11] CMP — Comparison Status (cleared on read)
  [10] UNDES — Underrun Error Status (Slave mode only) (cleared on read)
  [9] TXEMPTY — Transmission Registers Empty (cleared by writing FLEX_SPI_TDR)
  [8] NSSR — NSS Rising (cleared on read)
  [3] OVRES — Overrun Error Status (cleared on read)
  [2] MODF — Mode Fault Error (cleared on read)
  [1] TDRE — Transmit Data Register Empty (cleared by writing FLEX_SPI_TDR)
  [0] RDRF — Receive Data Register Full (cleared by reading FLEX_SPI_RDR)
0x414 FLEX_SPI_IER wo — SPI Interrupt Enable Register
  [31] RXFPTEF — RXFPTEF Interrupt Enable
  [30] TXFPTEF — TXFPTEF Interrupt Enable
  [29] RXFTHF — RXFTHF Interrupt Enable
  [28] RXFFF — RXFFF Interrupt Enable
  [27] RXFEF — RXFEF Interrupt Enable
  [26] TXFTHF — TXFTHF Interrupt Enable
  [25] TXFFF — TXFFF Interrupt Enable
  [24] TXFEF — TXFEF Interrupt Enable
  [11] CMP — Comparison Interrupt Enable
  [10] UNDES — Underrun Error Interrupt Enable
  [9] TXEMPTY — Transmission Registers Empty Enable
  [8] NSSR — NSS Rising Interrupt Enable
  [3] OVRES — Overrun Error Interrupt Enable
  [2] MODF — Mode Fault Error Interrupt Enable
  [1] TDRE — SPI Transmit Data Register Empty Interrupt Enable
  [0] RDRF — Receive Data Register Full Interrupt Enable
0x418 FLEX_SPI_IDR wo — SPI Interrupt Disable Register
  [31] RXFPTEF — RXFPTEF Interrupt Disable
  [30] TXFPTEF — TXFPTEF Interrupt Disable
  [29] RXFTHF — RXFTHF Interrupt Disable
  [28] RXFFF — RXFFF Interrupt Disable
  [27] RXFEF — RXFEF Interrupt Disable
  [26] TXFTHF — TXFTHF Interrupt Disable
  [25] TXFFF — TXFFF Interrupt Disable
  [24] TXFEF — TXFEF Interrupt Disable
  [11] CMP — Comparison Interrupt Disable
  [10] UNDES — Underrun Error Interrupt Disable
  [9] TXEMPTY — Transmission Registers Empty Disable
  [8] NSSR — NSS Rising Interrupt Disable
  [3] OVRES — Overrun Error Interrupt Disable
  [2] MODF — Mode Fault Error Interrupt Disable
  [1] TDRE — SPI Transmit Data Register Empty Interrupt Disable
  [0] RDRF — Receive Data Register Full Interrupt Disable
0x41C FLEX_SPI_IMR ro — SPI Interrupt Mask Register
  [31] RXFPTEF — RXFPTEF Interrupt Mask
  [30] TXFPTEF — TXFPTEF Interrupt Mask
  [29] RXFTHF — RXFTHF Interrupt Mask
  [28] RXFFF — RXFFF Interrupt Mask
  [27] RXFEF — RXFEF Interrupt Mask
  [26] TXFTHF — TXFTHF Interrupt Mask
  [25] TXFFF — TXFFF Interrupt Mask
  [24] TXFEF — TXFEF Interrupt Mask
  [11] CMP — Comparison Interrupt Mask
  [10] UNDES — Underrun Error Interrupt Mask
  [9] TXEMPTY — Transmission Registers Empty Mask
  [8] NSSR — NSS Rising Interrupt Mask
  [3] OVRES — Overrun Error Interrupt Mask
  [2] MODF — Mode Fault Error Interrupt Mask
  [1] TDRE — SPI Transmit Data Register Empty Interrupt Mask
  [0] RDRF — Receive Data Register Full Interrupt Mask
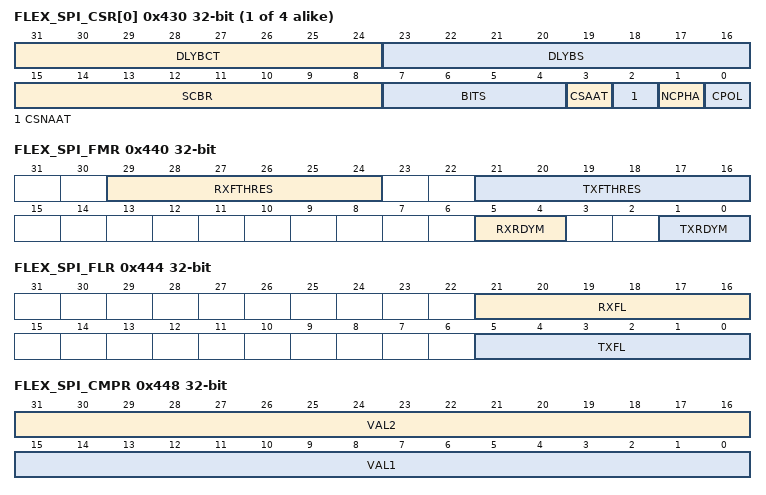
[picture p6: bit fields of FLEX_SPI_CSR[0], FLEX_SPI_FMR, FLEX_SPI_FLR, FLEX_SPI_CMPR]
{0x430+4i} FLEX_SPI_CSR[{i}] (i=0..3) — SPI Chip Select Register
  [31:24] DLYBCT — Delay Between Consecutive Transfers
  [23:16] DLYBS — Delay Before SPCK
  [15:8] SCBR — Serial Clock Bit Rate
  [7:4] BITS — Bits Per Transfer
    {v}=_{v+8}_BIT ({v+8} bits for transfer) (v=0..8)
  [3] CSAAT — Chip Select Active After Transfer
  [2] CSNAAT — Chip Select Not Active After Transfer (Ignored if CSAAT = 1)
  [1] NCPHA — Clock Phase
  [0] CPOL — Clock Polarity
0x440 FLEX_SPI_FMR — SPI FIFO Mode Register
  [29:24] RXFTHRES — Receive FIFO Threshold
  [21:16] TXFTHRES — Transmit FIFO Threshold
  [5:4] RXRDYM — Receive Data Register Full Mode
    0=ONE_DATA (RDRF will be at level '1' when at least one unread data is in the Receive FIFO.); 1=TWO_DATA (RDRF will be at level '1' when at least two unread data are in the Receive FIFO.Cannot be used when FLEX_SPI_MR.MSTR =1, or if FLEX_SPI_MR.PS =1.); 2=FOUR_DATA (RDRF will be at level '1' when at least four unread data are in the Receive FIFO.Cannot be used when FLEX_SPI_CSRx.BITS is greater than 0, or if FLEX_SPI_MR.MSTR =1, or if FLEX_SPI_MR.PS =1.)
  [1:0] TXRDYM — Transmit Data Register Empty Mode
    0=ONE_DATA (TDRE will be at level '1' when at least one data can be written in the Transmit FIFO.); 1=TWO_DATA (TDRE will be at level '1' when at least two data can be written in the Transmit FIFO.Cannot be used if FLEX_SPI_MR.PS =1.)
0x444 FLEX_SPI_FLR ro — SPI FIFO Level Register
  [21:16] RXFL — Receive FIFO Level
  [5:0] TXFL — Transmit FIFO Level
0x448 FLEX_SPI_CMPR — SPI Comparison Register
  [31:16] VAL2 — Second Comparison Value for Received Character
  [15:0] VAL1 — First Comparison Value for Received Character
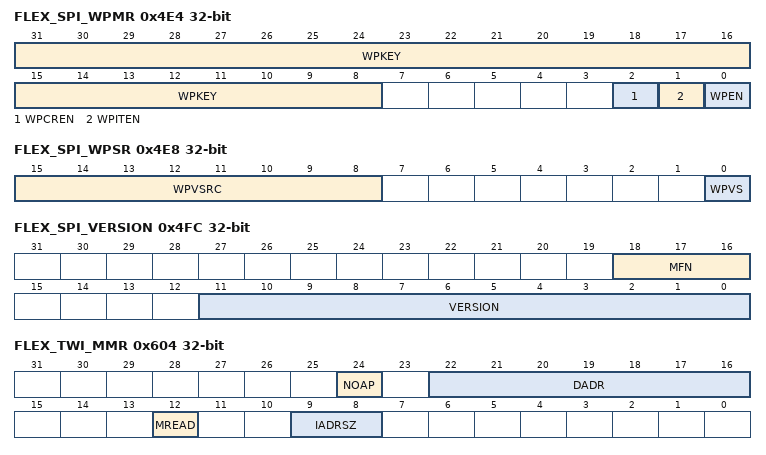
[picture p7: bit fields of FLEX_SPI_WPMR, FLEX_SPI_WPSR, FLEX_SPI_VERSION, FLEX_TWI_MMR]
0x4E4 FLEX_SPI_WPMR — SPI Write Protection Mode Register
  [31:8] WPKEY — Write Protection Key
    0x535049=PASSWD (Writing any other value in this field aborts the write operation of bits WPEN, WPITEN and WPCREN.Always reads as 0)
  [2] WPCREN — Write Protection Control Enable
  [1] WPITEN — Write Protection Interrupt Enable
  [0] WPEN — Write Protection Enable
0x4E8 FLEX_SPI_WPSR ro — SPI Write Protection Status Register
  [15:8] WPVSRC — Write Protection Violation Source
  [0] WPVS — Write Protection Violation Status
0x4FC FLEX_SPI_VERSION ro — SPI Version Register
  [18:16] MFN — Metal Fix Number
  [11:0] VERSION — Version of the Hardware Module
0x600 FLEX_TWI_CR wo — TWI Control Register
  [29] FIFODIS <DEFAULT> — FIFO Disable
  [28] FIFOEN <DEFAULT> — FIFO Enable
  [26] LOCKCLR <DEFAULT> — Lock Clear
  [24] THRCLR <DEFAULT> — Transmit Holding Register Clear
  [17] ACMDIS <DEFAULT> — Alternative Command Mode Disable
  [16] ACMEN <DEFAULT> — Alternative Command Mode Enable
  [15] CLEAR <DEFAULT> — Bus CLEAR Command
  [14] PECRQ <DEFAULT> — PEC Request
  [13] PECDIS <DEFAULT> — Packet Error Checking Disable
  [12] PECEN <DEFAULT> — Packet Error Checking Enable
  [11] SMBDIS <DEFAULT> — SMBus Mode Disabled
  [10] SMBEN <DEFAULT> — SMBus Mode Enabled
  [9] HSDIS <DEFAULT> — TWI High-Speed Mode Disabled
  [8] HSEN <DEFAULT> — TWI High-Speed Mode Enabled
  [7] SWRST <DEFAULT> — Software Reset
  [6] QUICK <DEFAULT> — SMBus Quick Command
  [5] SVDIS <DEFAULT> — TWI Slave Mode Disabled
  [4] SVEN <DEFAULT> — TWI Slave Mode Enabled
  [3] MSDIS <DEFAULT> — TWI Master Mode Disabled
  [2] MSEN <DEFAULT> — TWI Master Mode Enabled
  [1] STOP <DEFAULT> — Send a STOP Condition
  [0] START <DEFAULT> — Send a START Condition
  [29] FIFODIS <FIFO_ENABLED> — FIFO Disable
  [28] FIFOEN <FIFO_ENABLED> — FIFO Enable
  [26] TXFLCLR <FIFO_ENABLED> — Transmit FIFO Lock CLEAR
  [25] RXFCLR <FIFO_ENABLED> — Receive FIFO Clear
  [24] TXFCLR <FIFO_ENABLED> — Transmit FIFO Clear
  [17] ACMDIS <FIFO_ENABLED> — Alternative Command Mode Disable
  [16] ACMEN <FIFO_ENABLED> — Alternative Command Mode Enable
  [15] CLEAR <FIFO_ENABLED> — Bus CLEAR Command
  [14] PECRQ <FIFO_ENABLED> — PEC Request
  [13] PECDIS <FIFO_ENABLED> — Packet Error Checking Disable
  [12] PECEN <FIFO_ENABLED> — Packet Error Checking Enable
  [11] SMBDIS <FIFO_ENABLED> — SMBus Mode Disabled
  [10] SMBEN <FIFO_ENABLED> — SMBus Mode Enabled
  [9] HSDIS <FIFO_ENABLED> — TWI High-Speed Mode Disabled
  [8] HSEN <FIFO_ENABLED> — TWI High-Speed Mode Enabled
  [7] SWRST <FIFO_ENABLED> — Software Reset
  [6] QUICK <FIFO_ENABLED> — SMBus Quick Command
  [5] SVDIS <FIFO_ENABLED> — TWI Slave Mode Disabled
  [4] SVEN <FIFO_ENABLED> — TWI Slave Mode Enabled
  [3] MSDIS <FIFO_ENABLED> — TWI Master Mode Disabled
  [2] MSEN <FIFO_ENABLED> — TWI Master Mode Enabled
  [1] STOP <FIFO_ENABLED> — Send a STOP Condition
  [0] START <FIFO_ENABLED> — Send a START Condition
0x604 FLEX_TWI_MMR — TWI Master Mode Register
  [24] NOAP — No Auto-Stop On NACK Error
  [22:16] DADR — Device Address
  [12] MREAD — Master Read Direction
  [9:8] IADRSZ — Internal Device Address Size
    0=NONE (No internal device address); 1=_1_BYTE (One-byte internal device address); 2=_2_BYTE (Two-byte internal device address); 3=_3_BYTE (Three-byte internal device address)
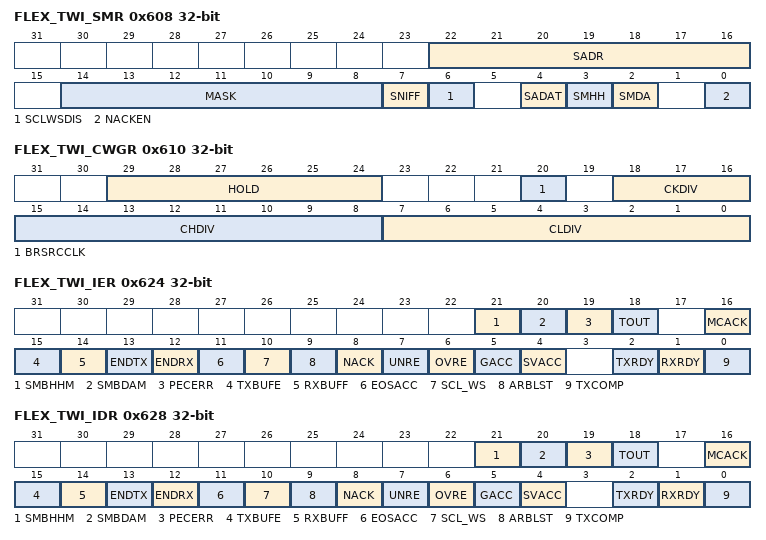
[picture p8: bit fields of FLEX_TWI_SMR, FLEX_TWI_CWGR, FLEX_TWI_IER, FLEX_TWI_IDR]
0x608 FLEX_TWI_SMR — TWI Slave Mode Register
  [22:16] SADR — Slave Address
  [14:8] MASK — Slave Address Mask
  [7] SNIFF — Slave Sniffer Mode
  [6] SCLWSDIS — Clock Wait State Disable
  [4] SADAT — Slave Address Treated as Data
  [3] SMHH — SMBus Host Header
  [2] SMDA — SMBus Default Address
  [0] NACKEN — Slave Receiver Data Phase NACK Enable
0x60C FLEX_TWI_IADR — TWI Internal Address Register
  [23:0] IADR — Internal Address
0x610 FLEX_TWI_CWGR — TWI Clock Waveform Generator Register
  [29:24] HOLD — TWD Hold Time Versus TWCK Falling
  [20] BRSRCCLK — Bit Rate Source Clock
    values as FLEX_SPI_MR.BRSRCCLK
  [18:16] CKDIV — Clock Divider
  [15:8] CHDIV — Clock High Divider
  [7:0] CLDIV — Clock Low Divider
0x620 FLEX_TWI_SR ro — TWI Status Register
  [26] SR <DEFAULT> — Start Repeated
  [25] SDA <DEFAULT> — SDA Line Value
  [24] SCL <DEFAULT> — SCL Line Value
  [23] LOCK <DEFAULT> — TWI Lock Due to Frame Errors
  [21] SMBHHM <DEFAULT> — SMBus Host Header Address Match (cleared on read)
  [20] SMBDAM <DEFAULT> — SMBus Default Address Match (cleared on read)
  [19] PECERR <DEFAULT> — PEC Error (cleared on read)
  [18] TOUT <DEFAULT> — Timeout Error (cleared on read)
  [16] MCACK <DEFAULT> — Master Code Acknowledge (cleared on read)
  [11] EOSACC <DEFAULT> — End Of Slave Access (cleared on read)
  [10] SCLWS <DEFAULT> — Clock Wait State
  [9] ARBLST <DEFAULT> — Arbitration Lost (cleared on read)
  [8] NACK <DEFAULT> — Not Acknowledged (cleared on read)
  [7] UNRE <DEFAULT> — Underrun Error (cleared on read)
  [6] OVRE <DEFAULT> — Overrun Error (cleared on read)
  [5] GACC <DEFAULT> — General Call Access (cleared on read)
  [4] SVACC <DEFAULT> — Slave Access
  [3] SVREAD <DEFAULT> — Slave Read
  [2] TXRDY <DEFAULT> — Transmit Holding Register Ready (cleared by writing FLEX_TWI_THR)
  [1] RXRDY <DEFAULT> — Receive Holding Register Ready (cleared when reading FLEX_TWI_RHR)
  [0] TXCOMP <DEFAULT> — Transmission Completed (cleared by writing FLEX_TWI_THR)
  [26] SR <FIFO_ENABLED> — Start Repeated
  [25] SDA <FIFO_ENABLED> — SDA Line Value
  [24] SCL <FIFO_ENABLED> — SCL Line Value
  [23] TXFLOCK <FIFO_ENABLED> — Transmit FIFO Lock
  [21] SMBHHM <FIFO_ENABLED> — SMBus Host Header Address Match (cleared on read)
  [20] SMBDAM <FIFO_ENABLED> — SMBus Default Address Match (cleared on read)
  [19] PECERR <FIFO_ENABLED> — PEC Error (cleared on read)
  [18] TOUT <FIFO_ENABLED> — Timeout Error (cleared on read)
  [16] MCACK <FIFO_ENABLED> — Master Code Acknowledge (cleared on read)
  [11] EOSACC <FIFO_ENABLED> — End Of Slave Access (cleared on read)
  [10] SCLWS <FIFO_ENABLED> — Clock Wait State
  [9] ARBLST <FIFO_ENABLED> — Arbitration Lost (cleared on read)
  [8] NACK <FIFO_ENABLED> — Not Acknowledged (cleared on read)
  [7] UNRE <FIFO_ENABLED> — Underrun Error (cleared on read)
  [6] OVRE <FIFO_ENABLED> — Overrun Error (cleared on read)
  [5] GACC <FIFO_ENABLED> — General Call Access (cleared on read)
  [4] SVACC <FIFO_ENABLED> — Slave Access
  [3] SVREAD <FIFO_ENABLED> — Slave Read
  [2] TXRDY <FIFO_ENABLED> — Transmit Holding Register Ready (cleared by writing FLEX_TWI_THR)
  [1] RXRDY <FIFO_ENABLED> — Receive Holding Register Ready (cleared when reading FLEX_TWI_RHR)
  [0] TXCOMP <FIFO_ENABLED> — Transmission Completed (cleared by writing FLEX_TWI_THR)
0x624 FLEX_TWI_IER wo — TWI Interrupt Enable Register
  [21] SMBHHM — SMBus Host Header Address Match Interrupt Enable
  [20] SMBDAM — SMBus Default Address Match Interrupt Enable
  [19] PECERR — PEC Error Interrupt Enable
  [18] TOUT — Timeout Error Interrupt Enable
  [16] MCACK — Master Code Acknowledge Interrupt Enable
  [15] TXBUFE — Transmit Buffer Empty Interrupt Enable
  [14] RXBUFF — Receive Buffer Full Interrupt Enable
  [13] ENDTX — End of Transmit Buffer Interrupt Enable
  [12] ENDRX — End of Receive Buffer Interrupt Enable
  [11] EOSACC — End Of Slave Access Interrupt Enable
  [10] SCL_WS — Clock Wait State Interrupt Enable
  [9] ARBLST — Arbitration Lost Interrupt Enable
  [8] NACK — Not Acknowledge Interrupt Enable
  [7] UNRE — Underrun Error Interrupt Enable
  [6] OVRE — Overrun Error Interrupt Enable
  [5] GACC — General Call Access Interrupt Enable
  [4] SVACC — Slave Access Interrupt Enable
  [2] TXRDY — Transmit Holding Register Ready Interrupt Enable
  [1] RXRDY — Receive Holding Register Ready Interrupt Enable
  [0] TXCOMP — Transmission Completed Interrupt Enable
0x628 FLEX_TWI_IDR wo — TWI Interrupt Disable Register
  [21] SMBHHM — SMBus Host Header Address Match Interrupt Disable
  [20] SMBDAM — SMBus Default Address Match Interrupt Disable
  [19] PECERR — PEC Error Interrupt Disable
  [18] TOUT — Timeout Error Interrupt Disable
  [16] MCACK — Master Code Acknowledge Interrupt Disable
  [15] TXBUFE — Transmit Buffer Empty Interrupt Disable
  [14] RXBUFF — Receive Buffer Full Interrupt Disable
  [13] ENDTX — End of Transmit Buffer Interrupt Disable
  [12] ENDRX — End of Receive Buffer Interrupt Disable
  [11] EOSACC — End Of Slave Access Interrupt Disable
  [10] SCL_WS — Clock Wait State Interrupt Disable
  [9] ARBLST — Arbitration Lost Interrupt Disable
  [8] NACK — Not Acknowledge Interrupt Disable
  [7] UNRE — Underrun Error Interrupt Disable
  [6] OVRE — Overrun Error Interrupt Disable
  [5] GACC — General Call Access Interrupt Disable
  [4] SVACC — Slave Access Interrupt Disable
  [2] TXRDY — Transmit Holding Register Ready Interrupt Disable
  [1] RXRDY — Receive Holding Register Ready Interrupt Disable
  [0] TXCOMP — Transmission Completed Interrupt Disable
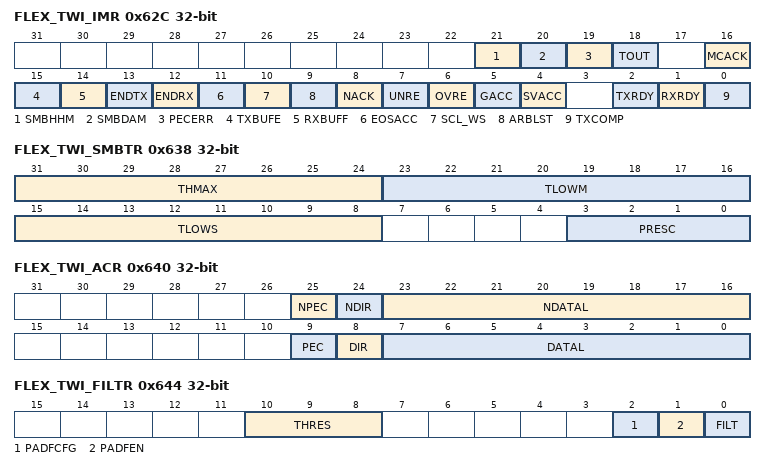
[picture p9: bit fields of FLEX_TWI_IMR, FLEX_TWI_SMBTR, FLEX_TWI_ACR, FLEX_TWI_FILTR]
0x62C FLEX_TWI_IMR ro — TWI Interrupt Mask Register
  [21] SMBHHM — SMBus Host Header Address Match Interrupt Mask
  [20] SMBDAM — SMBus Default Address Match Interrupt Mask
  [19] PECERR — PEC Error Interrupt Mask
  [18] TOUT — Timeout Error Interrupt Mask
  [16] MCACK — Master Code Acknowledge Interrupt Mask
  [15] TXBUFE — Transmit Buffer Empty Interrupt Mask
  [14] RXBUFF — Receive Buffer Full Interrupt Mask
  [13] ENDTX — End of Transmit Buffer Interrupt Mask
  [12] ENDRX — End of Receive Buffer Interrupt Mask
  [11] EOSACC — End Of Slave Access Interrupt Mask
  [10] SCL_WS — Clock Wait State Interrupt Mask
  [9] ARBLST — Arbitration Lost Interrupt Mask
  [8] NACK — Not Acknowledge Interrupt Mask
  [7] UNRE — Underrun Error Interrupt Mask
  [6] OVRE — Overrun Error Interrupt Mask
  [5] GACC — General Call Access Interrupt Mask
  [4] SVACC — Slave Access Interrupt Mask
  [2] TXRDY — Transmit Holding Register Ready Interrupt Mask
  [1] RXRDY — Receive Holding Register Ready Interrupt Mask
  [0] TXCOMP — Transmission Completed Interrupt Mask
0x630 FLEX_TWI_RHR ro — TWI Receive Holding Register
  [12:11] ASTATE <DEFAULT> — Acknowledge State (Slave Sniffer Mode only)
    0=NONE (No Acknowledge or Nacknowledge detected after previously logged data); 1=ACK (Acknowledge (A) detected after previously logged data); 2=NACK (Nacknowledge (NA) detected after previously logged data); 3=UNDEF (Not defined)
  [10] PSTATE <DEFAULT> — Stop State (Slave Sniffer Mode only)
  [9:8] SSTATE <DEFAULT> — Start State (Slave Sniffer Mode only)
    0=NOSTART (No START detected with the logged data); 1=START (START (S) detected with the logged data); 2=RSTART (Repeated START (Sr) detected with the logged data); 3=UNDEF (Not defined)
  [7:0] RXDATA <DEFAULT> — Master or Slave Receive Holding Data
  [8n+7:8n] RXDATA{n} <FIFO_ENABLED> (n=0..3) — Master or Slave Receive Holding Data {n}
0x634 FLEX_TWI_THR wo — TWI Transmit Holding Register
  [7:0] TXDATA <DEFAULT> — Master or Slave Transmit Holding Data
  [8n+7:8n] TXDATA{n} <FIFO_ENABLED> (n=0..3) — Master or Slave Transmit Holding Data {n}
0x638 FLEX_TWI_SMBTR — TWI SMBus Timing Register
  [31:24] THMAX — Clock High Maximum Cycles
  [23:16] TLOWM — Master Clock Stretch Maximum Cycles
  [15:8] TLOWS — Slave Clock Stretch Maximum Cycles
  [3:0] PRESC — SMBus Clock Prescaler
0x640 FLEX_TWI_ACR — TWI Alternative Command Register
  [25] NPEC — Next PEC Request (SMBus Mode only)
  [24] NDIR — Next Transfer Direction
  [23:16] NDATAL — Next Data Length
  [9] PEC — PEC Request (SMBus Mode only)
  [8] DIR — Transfer Direction
  [7:0] DATAL — Data Length
0x644 FLEX_TWI_FILTR — TWI Filter Register
  [10:8] THRES — Digital Filter Threshold
  [2] PADFCFG — PAD Filter Config
  [1] PADFEN — PAD Filter Enable
  [0] FILT — RX Digital Filter
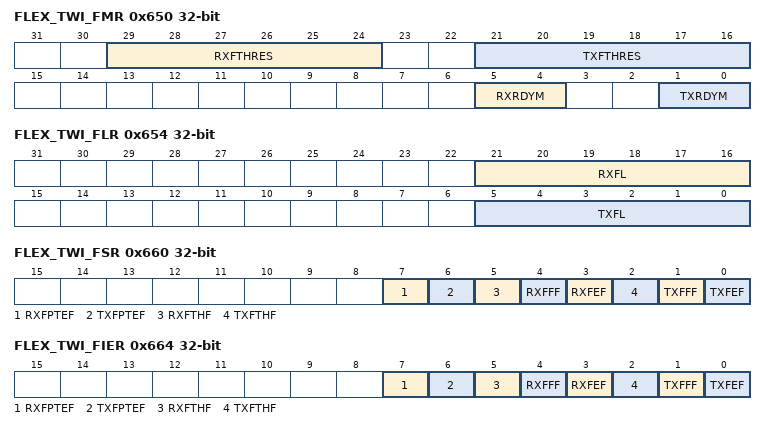
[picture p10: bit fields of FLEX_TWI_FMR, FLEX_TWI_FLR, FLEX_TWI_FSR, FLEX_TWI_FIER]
0x650 FLEX_TWI_FMR — TWI FIFO Mode Register
  [29:24] RXFTHRES — Receive FIFO Threshold
  [21:16] TXFTHRES — Transmit FIFO Threshold
  [5:4] RXRDYM — Receiver Ready Mode
    values as FLEX_US_FMR.RXRDYM
  [1:0] TXRDYM — Transmitter Ready Mode
    values as FLEX_US_FMR.TXRDYM
0x654 FLEX_TWI_FLR ro — TWI FIFO Level Register
  [21:16] RXFL — Receive FIFO Level
  [5:0] TXFL — Transmit FIFO Level
0x660 FLEX_TWI_FSR ro — TWI FIFO Status Register
  [7] RXFPTEF — Receive FIFO Pointer Error Flag
  [6] TXFPTEF — Transmit FIFO Pointer Error Flag
  [5] RXFTHF — Receive FIFO Threshold Flag
  [4] RXFFF — Receive FIFO Full Flag
  [3] RXFEF — Receive FIFO Empty Flag
  [2] TXFTHF — Transmit FIFO Threshold Flag (cleared on read)
  [1] TXFFF — Transmit FIFO Full Flag (cleared on read)
  [0] TXFEF — Transmit FIFO Empty Flag (cleared on read)
0x664 FLEX_TWI_FIER wo — TWI FIFO Interrupt Enable Register
  [7] RXFPTEF — RXFPTEF Interrupt Enable
  [6] TXFPTEF — TXFPTEF Interrupt Enable
  [5] RXFTHF — RXFTHF Interrupt Enable
  [4] RXFFF — RXFFF Interrupt Enable
  [3] RXFEF — RXFEF Interrupt Enable
  [2] TXFTHF — TXFTHF Interrupt Enable
  [1] TXFFF — TXFFF Interrupt Enable
  [0] TXFEF — TXFEF Interrupt Enable
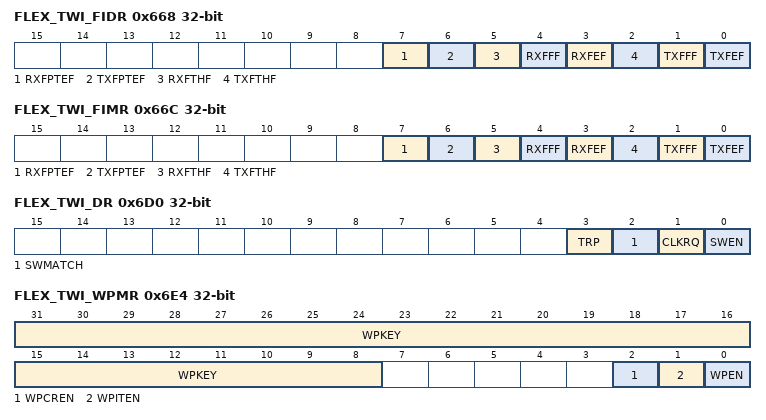
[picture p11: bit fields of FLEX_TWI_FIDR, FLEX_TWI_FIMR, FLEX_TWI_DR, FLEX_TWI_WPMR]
0x668 FLEX_TWI_FIDR wo — TWI FIFO Interrupt Disable Register
  [7] RXFPTEF — RXFPTEF Interrupt Disable
  [6] TXFPTEF — TXFPTEF Interrupt Disable
  [5] RXFTHF — RXFTHF Interrupt Disable
  [4] RXFFF — RXFFF Interrupt Disable
  [3] RXFEF — RXFEF Interrupt Disable
  [2] TXFTHF — TXFTHF Interrupt Disable
  [1] TXFFF — TXFFF Interrupt Disable
  [0] TXFEF — TXFEF Interrupt Disable
0x66C FLEX_TWI_FIMR ro — TWI FIFO Interrupt Mask Register
  [7] RXFPTEF — RXFPTEF Interrupt Mask
  [6] TXFPTEF — TXFPTEF Interrupt Mask
  [5] RXFTHF — RXFTHF Interrupt Mask
  [4] RXFFF — RXFFF Interrupt Mask
  [3] RXFEF — RXFEF Interrupt Mask
  [2] TXFTHF — TXFTHF Interrupt Mask
  [1] TXFFF — TXFFF Interrupt Mask
  [0] TXFEF — TXFEF Interrupt Mask
0x6D0 FLEX_TWI_DR ro — TWI Debug Register
  [3] TRP — Transfer Pending
  [2] SWMATCH — SleepWalking Match
  [1] CLKRQ — Clock Request
  [0] SWEN — SleepWalking Enable
0x6E4 FLEX_TWI_WPMR — TWI Write Protection Mode Register
  [31:8] WPKEY — Write Protection Key
    0x545749=PASSWD (Writing any other value in this field aborts the write operation of bits WPEN, WPITEN and WPCREN.Always reads as 0)
  [2] WPCREN — Write Protection Control Enable
  [1] WPITEN — Write Protection Interrupt Enable
  [0] WPEN — Write Protection Enable
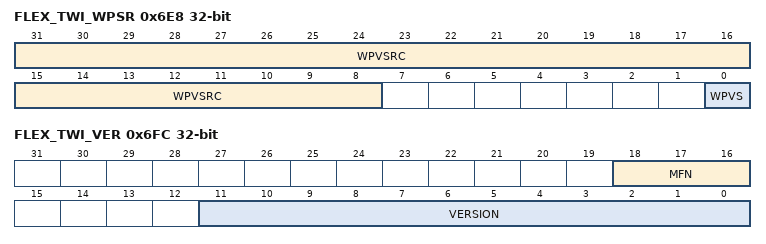
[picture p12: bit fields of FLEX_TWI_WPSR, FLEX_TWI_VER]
0x6E8 FLEX_TWI_WPSR ro — TWI Write Protection Status Register
  [31:8] WPVSRC — Write Protection Violation Source
  [0] WPVS — Write Protect Violation Status
0x6FC FLEX_TWI_VER ro — TWI Version Register
  fields as FLEX_SPI_VERSION
